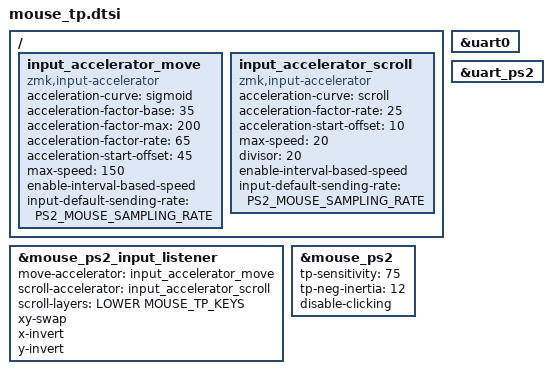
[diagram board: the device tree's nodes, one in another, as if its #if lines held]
#ifdef HAS_MOUSE_TP
  #include <dt-bindings/zmk/mouse.h>
  #include <dt-bindings/zmk/mouse_settings.h>
  #include <behaviors/mouse_keys.dtsi>
  #include <behaviors/mouse_setting.dtsi>

  // ランタイム感度調整用キーコード（これらは通信が止まらない安全なキーです）
  #define U_MSS_TP_S_I  &mms MS_TP_SENSITIVITY_INCR
  #define U_MSS_TP_S_D  &mms MS_TP_SENSITIVITY_DECR
  #define U_MSS_TP_V6_I &mms MS_TP_VALUE6_INCR
  #define U_MSS_TP_V6_D &mms MS_TP_VALUE6_DECR
  #define U_MSS_TP_NI_I &mms MS_TP_NEG_INERTIA_INCR
  #define U_MSS_TP_NI_D &mms MS_TP_NEG_INERTIA_DECR
  #define U_MSS_TP_PT_I &mms MS_TP_PTS_THRESHOLD_INCR
  #define U_MSS_TP_PT_D &mms MS_TP_PTS_THRESHOLD_DECR
  #define U_MSS_LOG     &mms MS_LOG

  #ifdef MOUSE_PS2_DT_PRESENT
    #define PS2_MOUSE_SAMPLING_RATE 100

    / {
        input_accelerator_move: input_accelerator_move {
          status = "okay";
          compatible = "zmk,input-accelerator";
          acceleration-curve = "sigmoid";
          acceleration-factor-base = <35>;   // ★10 -> 35: 通常の移動速度を大幅に引き上げ
          acceleration-factor-max = <200>;   // ★150 -> 200: 素早く動かした時の最高速をアップ
          acceleration-factor-rate = <65>;   // ★50 -> 65: 指を入れた瞬間の立ち上がりを鋭くする
          acceleration-start-offset = <45>;  // ★100 -> 45: 軽い力ですぐ加速が始まるようにする
          max-speed = <150>;                 // ★110 -> 150: 速度の上限を解放
          enable-interval-based-speed;
          input-default-sending-rate = <PS2_MOUSE_SAMPLING_RATE>;
        };

        input_accelerator_scroll: input_accelerator_scroll {
          status = "okay";
          compatible = "zmk,input-accelerator";
          acceleration-curve = "scroll";
          acceleration-factor-rate = <25>;
          acceleration-start-offset = <10>;
          max-speed = <20>;
          divisor = <20>;
          enable-interval-based-speed;
          input-default-sending-rate = <PS2_MOUSE_SAMPLING_RATE>;
        };
    };

    &mouse_ps2_input_listener {
      status = "okay";
      move-accelerator = <&input_accelerator_move>;
      scroll-accelerator = <&input_accelerator_scroll>;
      scroll-layers = <LOWER MOUSE_TP_KEYS>;
      xy-swap;
      x-invert;
      y-invert;
      // layer-toggle = <MOUSE_TP>;
      // layer-toggle-delay-ms = <300>;
      // layer-toggle-timeout-ms = <125>;
      // layer-toggle-require-prior-idle-ms = <300>;
    };

    &mouse_ps2 {
      status = "okay";
      tp-sensitivity = <75>;   // ★45 -> 75: センサーの基本感度を実用レベルまで引き上げ
      tp-neg-inertia = <12>;
      disable-clicking;
    };

    #ifdef MOUSE_PS2_DRIVER_UART
      &uart0 { status = "okay"; };
      &uart_ps2 { status = "okay"; };
    #else
      &gpio_ps2 { status = "okay"; };
    #endif
  #endif
#endif
